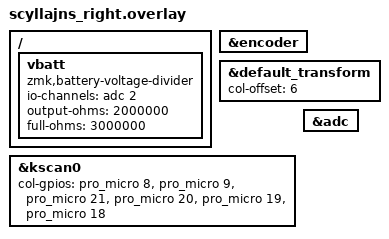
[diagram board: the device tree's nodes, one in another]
/*
 * Copyright (c) 2020 The ZMK Contributors
 * SPDX-License-Identifier: MIT
 *
 * ScyllaJNS — lado direito
 * Mesmos pinos físicos da esquerda, col-offset = 6 mapeia para C6–C11
 */

#include "scyllajns.dtsi"

/* Encoder EC11 habilitado apenas no lado direito */
&encoder {
    status = "okay";
};

&default_transform {
    col-offset = <6>;
};

&kscan0 {
    col-gpios
        = <&pro_micro 8  GPIO_ACTIVE_HIGH>   /* C6  — P1.04 */
        , <&pro_micro 9  GPIO_ACTIVE_HIGH>   /* C7  — P1.06 */
        , <&pro_micro 21 GPIO_ACTIVE_HIGH>   /* C8  — P0.31 */
        , <&pro_micro 20 GPIO_ACTIVE_HIGH>   /* C9  — P0.29 */
        , <&pro_micro 19 GPIO_ACTIVE_HIGH>   /* C10 — P0.02 */
        , <&pro_micro 18 GPIO_ACTIVE_HIGH>   /* C11 — P1.15 */
        ;
};

/ {
    vbatt: vbatt {
        compatible = "zmk,battery-voltage-divider";
        io-channels = <&adc 2>;
        output-ohms = <2000000>;
        full-ohms = <3000000>;
    };
};

&adc {
    status = "okay";
};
